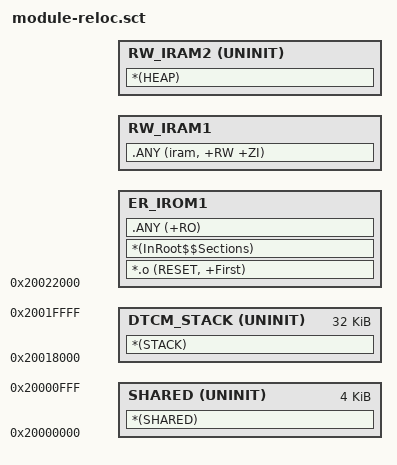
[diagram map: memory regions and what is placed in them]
LR_IROM1 0x20022000 RELOC {    ; load region size_region
  ER_IROM1 +0 {  ; load address = execution address
   *.o (RESET, +First)
   *(InRoot$$Sections)
   .ANY (+RO)
  }
  RW_IRAM1 +0 {  ; RW data
   .ANY (iram, +RW +ZI)
  }
  RW_IRAM2 +0 UNINIT  {  ; RW data
   *(HEAP)
  }
}
LR_IRAM1 0x20000000 0x00001000  {
  SHARED 0x20000000 UNINIT 0x00001000  {  ; DTCM
    *(SHARED)
  }
  DTCM_STACK 0x20018000 UNINIT 0x00008000  {  ; DTCM    
   *(STACK)
  }
}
